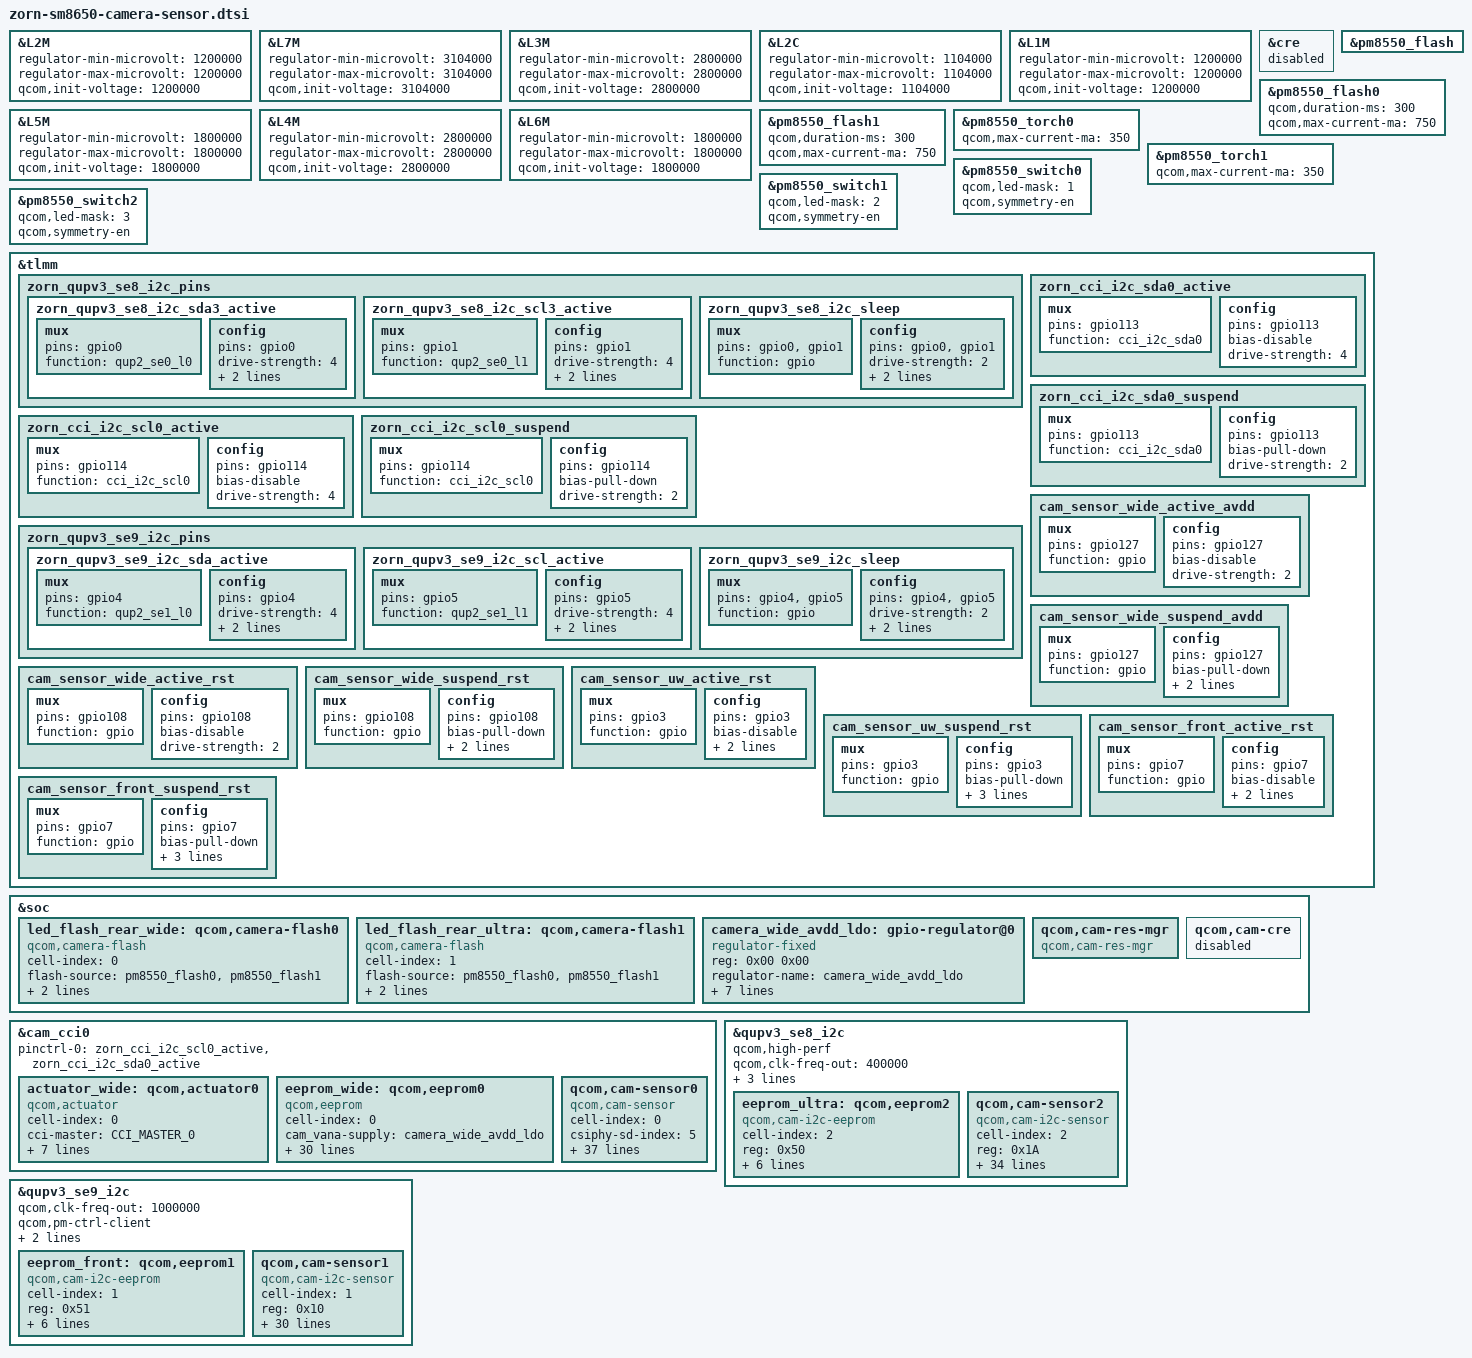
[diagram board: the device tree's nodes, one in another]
#include <dt-bindings/msm-camera.h>

&L2M {
	regulator-min-microvolt = <1200000>;
	regulator-max-microvolt = <1200000>;
	qcom,init-voltage = <1200000>;
};
&L7M {
	regulator-min-microvolt = <3104000>;
	regulator-max-microvolt = <3104000>;
	qcom,init-voltage = <3104000>;
};
&L3M {
	regulator-min-microvolt = <2800000>;
	regulator-max-microvolt = <2800000>;
	qcom,init-voltage = <2800000>;
};
&L2C {
	regulator-min-microvolt = <1104000>;
	regulator-max-microvolt = <1104000>;
	qcom,init-voltage = <1104000>;
};
&L1M {
	regulator-min-microvolt = <1200000>;
	regulator-max-microvolt = <1200000>;
	qcom,init-voltage = <1200000>;
};
&L5M {
	regulator-min-microvolt = <1800000>;
	regulator-max-microvolt = <1800000>;
	qcom,init-voltage = <1800000>;
};
&L4M {
	regulator-min-microvolt = <2800000>;
	regulator-max-microvolt = <2800000>;
	qcom,init-voltage = <2800000>;
};
&L6M {
	regulator-min-microvolt = <1800000>;
	regulator-max-microvolt = <1800000>;
	qcom,init-voltage = <1800000>;
};
&cre {
	status = "disabled";
};
&pm8550_flash {
	status = "ok";
};
&pm8550_flash0 {
	qcom,duration-ms = <300>;
	qcom,max-current-ma = <750>;
};
&pm8550_flash1 {
	qcom,duration-ms = <300>;
	qcom,max-current-ma = <750>;
};
&pm8550_torch0{
	qcom,max-current-ma = <350>;
};
&pm8550_torch1{
	qcom,max-current-ma = <350>;
};
&pm8550_switch0 {
	qcom,led-mask = <1>;
	qcom,symmetry-en;
};
&pm8550_switch1 {
	qcom,led-mask = <2>;
	qcom,symmetry-en;
};
&pm8550_switch2 {
	qcom,led-mask = <3>;
	qcom,symmetry-en;
};
&tlmm {
	zorn_qupv3_se8_i2c_pins: zorn_qupv3_se8_i2c_pins {
		zorn_qupv3_se8_i2c_sda3_active: zorn_qupv3_se8_i2c_sda3_active {
			mux {
				pins = "gpio0";
				function = "qup2_se0_l0";
			};
			config {
				pins = "gpio0";
				drive-strength = <4>;
				bias-disable; /* NO PULL */
				qcom,apps;
			};
		};
		zorn_qupv3_se8_i2c_scl3_active: zorn_qupv3_se8_i2c_scl3_active {
			mux {
				pins = "gpio1";
				function = "qup2_se0_l1";
			};
			config {
				pins = "gpio1";
				drive-strength = <4>;
				bias-disable; /* NO PULL */
				qcom,apps;
			};
		};
		zorn_qupv3_se8_i2c_sleep: zorn_qupv3_se8_i2c_sleep {
			mux {
				pins = "gpio0", "gpio1";
				function = "gpio";
			};
			config {
				pins = "gpio0", "gpio1";
				drive-strength = <2>;
				bias-disable;
				qcom,remote;
			};
		};
	};
	zorn_cci_i2c_sda0_active: zorn_cci_i2c_sda0_active {
		mux {
			/* CLK, DATA */
			pins = "gpio113";
			function = "cci_i2c_sda0";
		};
		config {
			pins = "gpio113";
			bias-disable; /* NO PULL */
			drive-strength = <4>; /* 4 MA */
		};
	};
	zorn_cci_i2c_sda0_suspend: zorn_cci_i2c_sda0_suspend {
		mux {
			/* CLK, DATA */
			pins = "gpio113";
			function = "cci_i2c_sda0";
		};
		config {
			pins = "gpio113";
			bias-pull-down; /* PULL DOWN */
			drive-strength = <2>; /* 2 MA */
		};
	};
	zorn_cci_i2c_scl0_active: zorn_cci_i2c_scl0_active {
		mux {
			/* CLK, DATA */
			pins = "gpio114";
			function = "cci_i2c_scl0";
		};
		config {
			pins = "gpio114";
			bias-disable; /* NO PULL */
			drive-strength = <4>; /* 4 MA */
		};
	};
	zorn_cci_i2c_scl0_suspend: zorn_cci_i2c_scl0_suspend {
		mux {
			/* CLK, DATA */
			pins = "gpio114";
			function = "cci_i2c_scl0";
		};
		config {
			pins = "gpio114";
			bias-pull-down; /* PULL DOWN */
			drive-strength = <2>; /* 2 MA */
		};
	};

	zorn_qupv3_se9_i2c_pins: zorn_qupv3_se9_i2c_pins {
		zorn_qupv3_se9_i2c_sda_active: zorn_qupv3_se9_i2c_sda_active {
			mux {
				pins = "gpio4";
				function = "qup2_se1_l0";
			};

			config {
				pins = "gpio4";
				drive-strength = <4>;
				bias-disable; /* NO PULL */
				qcom,apps;
			};
		};

		zorn_qupv3_se9_i2c_scl_active: zorn_qupv3_se9_i2c_scl_active {
			mux {
				pins = "gpio5";
				function = "qup2_se1_l1";
			};

			config {
				pins = "gpio5";
				drive-strength = <4>;
				bias-disable; /* NO PULL */
				qcom,apps;
			};
		};

		zorn_qupv3_se9_i2c_sleep: zorn_qupv3_se9_i2c_sleep {
			mux {
				pins = "gpio4", "gpio5";
				function = "gpio";
			};

			config {
				pins = "gpio4", "gpio5";
				drive-strength = <2>;
				bias-pull-down;
				qcom,remote;
			};
		};
	};


	cam_sensor_wide_active_avdd: cam_sensor_wide_active_avdd {
		mux {
			pins = "gpio127";
			function = "gpio";
		};
		config {
			pins = "gpio127";
			bias-disable; /* No PULL */
			drive-strength = <2>; /* 2 MA */
		};
	};
	cam_sensor_wide_suspend_avdd: cam_sensor_wide_suspend_avdd {
		mux {
			pins = "gpio127";
			function = "gpio";
		};
		config {
			pins = "gpio127";
			bias-pull-down; /* PULL DOWN */
			drive-strength = <2>; /* 2 MA */
			output-low;
		};
	};


	cam_sensor_wide_active_rst: cam_sensor_wide_active_rst {
		mux {
			pins = "gpio108";
			function = "gpio";
		};
		config {
			pins = "gpio108";
			bias-disable; /* No PULL */
			drive-strength = <2>; /* 2 MA */
		};
	};
	cam_sensor_wide_suspend_rst: cam_sensor_wide_suspend_rst {
		mux {
			pins = "gpio108";
			function = "gpio";
		};
		config {
			pins = "gpio108";
			bias-pull-down; /* PULL DOWN */
			drive-strength = <2>; /* 2 MA */
			output-low;
		};
	};
	cam_sensor_uw_active_rst: cam_sensor_uw_active_rst {
		mux {
			pins = "gpio3";
			function = "gpio";
		};
		config {
			pins = "gpio3";
			bias-disable; /* No PULL */
			drive-strength = <2>; /* 2 MA */
			qcom,apps;
		};
	};
	cam_sensor_uw_suspend_rst: cam_sensor_uw_suspend_rst {
		mux {
			pins = "gpio3";
			function = "gpio";
		};
		config {
			pins = "gpio3";
			bias-pull-down; /* PULL DOWN */
			drive-strength = <2>; /* 2 MA */
			output-low;
			qcom,remote;
		};
	};
	cam_sensor_front_active_rst: cam_sensor_front_active_rst {
		mux {
			pins = "gpio7";
			function = "gpio";
		};
		config {
			pins = "gpio7";
			bias-disable; /* No PULL */
			drive-strength = <2>; /* 2 MA */
			qcom,apps;
		};
	};
	cam_sensor_front_suspend_rst: cam_sensor_front_suspend_rst {
		mux {
			pins = "gpio7";
			function = "gpio";
		};
		config {
			pins = "gpio7";
			bias-pull-down; /* PULL DOWN */
			drive-strength = <2>; /* 2 MA */
			output-low;
			qcom,remote;
		};
	};
};
&soc {
	led_flash_rear_wide: qcom,camera-flash0 {
		cell-index = <0>;
		compatible = "qcom,camera-flash";
		flash-source = <&pm8550_flash0 &pm8550_flash1>;
		torch-source = <&pm8550_torch0 &pm8550_torch1>;
		switch-source = <&pm8550_switch2>;
		status = "ok";
	};
	led_flash_rear_ultra: qcom,camera-flash1 {
		cell-index = <1>;
		compatible = "qcom,camera-flash";
		flash-source = <&pm8550_flash0 &pm8550_flash1>;
		torch-source = <&pm8550_torch0 &pm8550_torch1>;
		switch-source = <&pm8550_switch2>;
		status = "ok";
	};
	camera_wide_avdd_ldo: gpio-regulator@0 {
		compatible = "regulator-fixed";
		reg = <0x00 0x00>;
		regulator-name = "camera_wide_avdd_ldo";
		regulator-min-microvolt = <2800000>;
		regulator-max-microvolt = <2800000>;
		regulator-enable-ramp-delay = <100>;
		enable-active-high;
		gpio = <&tlmm 127 0>;
		pinctrl-names = "wide_avdd_active", "wide_avdd_suspend";
		pinctrl-0 = <&cam_sensor_wide_active_avdd
					 &cam_sensor_wide_suspend_avdd>;
	};
	qcom,cam-res-mgr {
		compatible = "qcom,cam-res-mgr";
		status = "ok";
	};
	qcom,cam-cre {
		status = "disabled";
	};
};
&cam_cci0 {
	pinctrl-0 = <&zorn_cci_i2c_scl0_active &zorn_cci_i2c_sda0_active>;
	actuator_wide: qcom,actuator0 {
		cell-index = <0>;
		compatible = "qcom,actuator";
		cci-master = <CCI_MASTER_0>;
		cam_vaf-supply = <&L7M>;
		cam_vio-supply = <&L10B>;
		regulator-names = "cam_vaf", "cam_vio";
		rgltr-cntrl-support;
		rgltr-min-voltage = <3104000 1800000>;
		rgltr-max-voltage = <3104000 1800000>;
		rgltr-load-current = <150000 106000>;
		status = "ok";
	};
	eeprom_wide: qcom,eeprom0 {
		cell-index = <0>;
		compatible = "qcom,eeprom";
		cam_vana-supply = <&camera_wide_avdd_ldo>;
		cam_vio-supply = <&L10B>;
		cam_vdig-supply = <&L2C>;
		cam_vaf-supply = <&L7M>;
		cam_bob2-supply = <&BOB2>;
		cam_clk-supply = <&cam_cc_titan_top_gdsc>;
		regulator-names = "cam_vana", "cam_vio",
			"cam_vdig", "cam_vaf", "cam_clk", "cam_bob2";
		rgltr-cntrl-support;
		pwm-switch;
		rgltr-min-voltage = <2800000 1800000 1104000 3104000 0 2704000>;
		rgltr-max-voltage = <2800000 1800000 1104000 3104000 0 3296000>;
		rgltr-load-current = <102000 106000 796500 150000 0 2500000>;
		gpio-no-mux = <0>;
		pinctrl-names = "cam_default", "cam_suspend";
		pinctrl-0 = <&cam_sensor_mclk0_active
			&cam_sensor_wide_active_rst>;
		pinctrl-1 = <&cam_sensor_mclk0_suspend
			&cam_sensor_wide_suspend_rst>;
		gpios = <&tlmm 100 0>, <&tlmm 108 0>;
		gpio-reset = <1>;
		gpio-req-tbl-num = <0 1>;
		gpio-req-tbl-flags = <1 0>;
		gpio-req-tbl-label = "CAMIF_MCLK0", "CAM_RESET_WIDE";
		cci-master = <CCI_MASTER_0>;
		clocks = <&camcc CAM_CC_MCLK0_CLK>;
		clock-names = "cam_clk";
		clock-cntl-level = "nominal";
		clock-rates = <19200000>;
		status = "ok";
	};
	qcom,cam-sensor0 {
		cell-index = <0>;
		compatible = "qcom,cam-sensor";
		csiphy-sd-index = <5>;
		actuator-src = <&actuator_wide>;
		led-flash-src = <&led_flash_rear_wide>;
		eeprom-src = <&eeprom_wide>;
		sensor-position-roll = <90>;
		sensor-position-pitch = <0>;
		sensor-position-yaw = <180>;
		cam_vana-supply = <&camera_wide_avdd_ldo>;
		cam_vio-supply = <&L10B>;
		cam_vdig-supply = <&L2C>;
		cam_vaf-supply = <&L7M>;
		cam_bob2-supply = <&BOB2>;
		cam_clk-supply = <&cam_cc_titan_top_gdsc>;
		regulator-names = "cam_vana", "cam_vio",
			"cam_vdig", "cam_vaf", "cam_clk", "cam_bob2";
		rgltr-cntrl-support;
		pwm-switch;
		rgltr-min-voltage = <2800000 1800000 1104000 3104000 0 2704000>;
		rgltr-max-voltage = <2800000 1800000 1104000 3104000 0 3296000>;
		rgltr-load-current = <102000 106000 796500 150000 0 2500000>;
		gpio-no-mux = <0>;
		pinctrl-names = "cam_default", "cam_suspend";
		pinctrl-0 = <&cam_sensor_mclk0_active
			&cam_sensor_wide_active_rst>;
		pinctrl-1 = <&cam_sensor_mclk0_suspend
			&cam_sensor_wide_suspend_rst>;
		gpios = <&tlmm 100 0>, <&tlmm 108 0>;
		gpio-reset = <1>;
		gpio-req-tbl-num = <0 1>;
		gpio-req-tbl-flags = <1 0>;
		gpio-req-tbl-label = "CAMIF_MCLK0", "CAM_RESET_WIDE";
		cci-master = <CCI_MASTER_0>;
		clocks = <&camcc CAM_CC_MCLK0_CLK>;
		clock-names = "cam_clk";
		clock-cntl-level = "nominal";
		clock-rates = <19200000>;
		status = "ok";
	};
};

&qupv3_se8_i2c {
	status = "ok";
	qcom,high-perf;
	qcom,clk-freq-out = <400000>;
	qcom,pm-ctrl-client;
	pinctrl-0 = <&zorn_qupv3_se8_i2c_sda3_active>, <&zorn_qupv3_se8_i2c_scl3_active>;

    eeprom_ultra: qcom,eeprom2 {
		cell-index = <2>;
		reg = <0x50>;
		compatible = "qcom,cam-i2c-eeprom";
		cam_vio-supply = <&L6M>;
		regulator-names = "cam_vio";
		rgltr-cntrl-support;
		rgltr-min-voltage = <1800000>;
		rgltr-max-voltage = <1800000>;
		rgltr-load-current = <300>;
		status = "ok";
	};

	qcom,cam-sensor2 {
		cell-index = <2>;
		reg = <0x1A>;
		compatible = "qcom,cam-i2c-sensor";
		csiphy-sd-index = <2>;
		led-flash-src = <&led_flash_rear_ultra>;
		sensor-position-roll = <90>;
		sensor-position-pitch = <0>;
		sensor-position-yaw = <180>;
		eeprom-src = <&eeprom_ultra>;
		cam_vana-supply = <&L4M>;
		cam_vio-supply = <&L6M>;
		cam_vdig-supply = <&L2M>;
		cam_clk-supply = <&cam_cc_titan_top_gdsc>;
		regulator-names = "cam_vana", "cam_vio", "cam_vdig", "cam_clk";
		rgltr-cntrl-support;
		aon-camera-id = <AON_CAM2>;
		rgltr-min-voltage = <2800000 1800000 1200000 0>;
		rgltr-max-voltage = <2800000 1800000 1200000 0>;
		rgltr-load-current = <57900 300 216200 0>;
		gpio-no-mux = <0>;
		pinctrl-names = "cam_default", "cam_suspend";
		pinctrl-0 = <&cam_sensor_mclk2_active
					&cam_sensor_uw_active_rst
					&cam_sensor_ponv_front_active>;
		pinctrl-1 = <&cam_sensor_mclk2_suspend
					&cam_sensor_uw_suspend_rst
					&cam_sensor_ponv_front_suspend>;
		gpios = <&tlmm 102 0>,
			<&tlmm 3 0>,
			<&tlmm 2 0>;
		gpio-reset = <1>;
		gpio-standby = <2>;
		gpio-req-tbl-num = <0 1 2>;
		gpio-req-tbl-flags = <1 0 0>;
		gpio-req-tbl-label = "CAMIF_MCLK2",
					"CAM_RESET_ULTRA",
					"CAM_STANDBY";
		clocks = <&camcc CAM_CC_MCLK2_CLK>;
		clock-names = "cam_clk";
		clock-cntl-level = "nominal";
		clock-rates = <19200000>;
		status = "ok";
	};
};

&qupv3_se9_i2c {
	status = "ok";
	qcom,clk-freq-out = <1000000>;
	qcom,pm-ctrl-client;

	pinctrl-0 = <&zorn_qupv3_se9_i2c_sda_active>, <&zorn_qupv3_se9_i2c_scl_active>;
    eeprom_front: qcom,eeprom1 {
		cell-index = <1>;
		reg = <0x51>;
		compatible = "qcom,cam-i2c-eeprom";
		cam_vio-supply = <&L5M>;
		regulator-names = "cam_vio";
		rgltr-cntrl-support;
		rgltr-min-voltage = <1800000>;
		rgltr-max-voltage = <1800000>;
		rgltr-load-current = <300>;
		status = "ok";
	};
	qcom,cam-sensor1 {
		cell-index = <1>;
		reg = <0x10>;
		compatible = "qcom,cam-i2c-sensor";
		csiphy-sd-index = <4>;
		sensor-position-roll = <270>;
		sensor-position-pitch = <0>;
		sensor-position-yaw = <0>;
		eeprom-src = <&eeprom_front>;
		cam_vana-supply = <&L3M>;
		cam_vio-supply = <&L5M>;
		cam_vdig-supply = <&L1M>;
		cam_clk-supply = <&cam_cc_titan_top_gdsc>;
		regulator-names = "cam_vana", "cam_vio",
			"cam_vdig", "cam_clk";
		rgltr-cntrl-support;
		aon-camera-id = <AON_CAM1>;
		rgltr-min-voltage = <2800000 1800000 1200000 0>;
		rgltr-max-voltage = <2800000 1800000 1200000 0>;
		rgltr-load-current = <43500 300 93000 0>;
		gpio-no-mux = <0>;
		pinctrl-names = "cam_default", "cam_suspend";
		pinctrl-0 = <&cam_sensor_mclk4_active
			&cam_sensor_front_active_rst>;
		pinctrl-1 = <&cam_sensor_mclk4_suspend
			&cam_sensor_front_suspend_rst>;
		gpios = <&tlmm 104 0>, <&tlmm 7 0>;
		gpio-reset = <1>;
		gpio-req-tbl-num = <0 1>;
		gpio-req-tbl-flags = <1 0>;
		gpio-req-tbl-label = "CAMIF_MCLK4", "CAM_RESET_FRONT";
		clocks = <&camcc CAM_CC_MCLK4_CLK>;
		clock-names = "cam_clk";
		clock-cntl-level = "nominal";
		clock-rates = <19200000>;
		status = "ok";
	};

};
